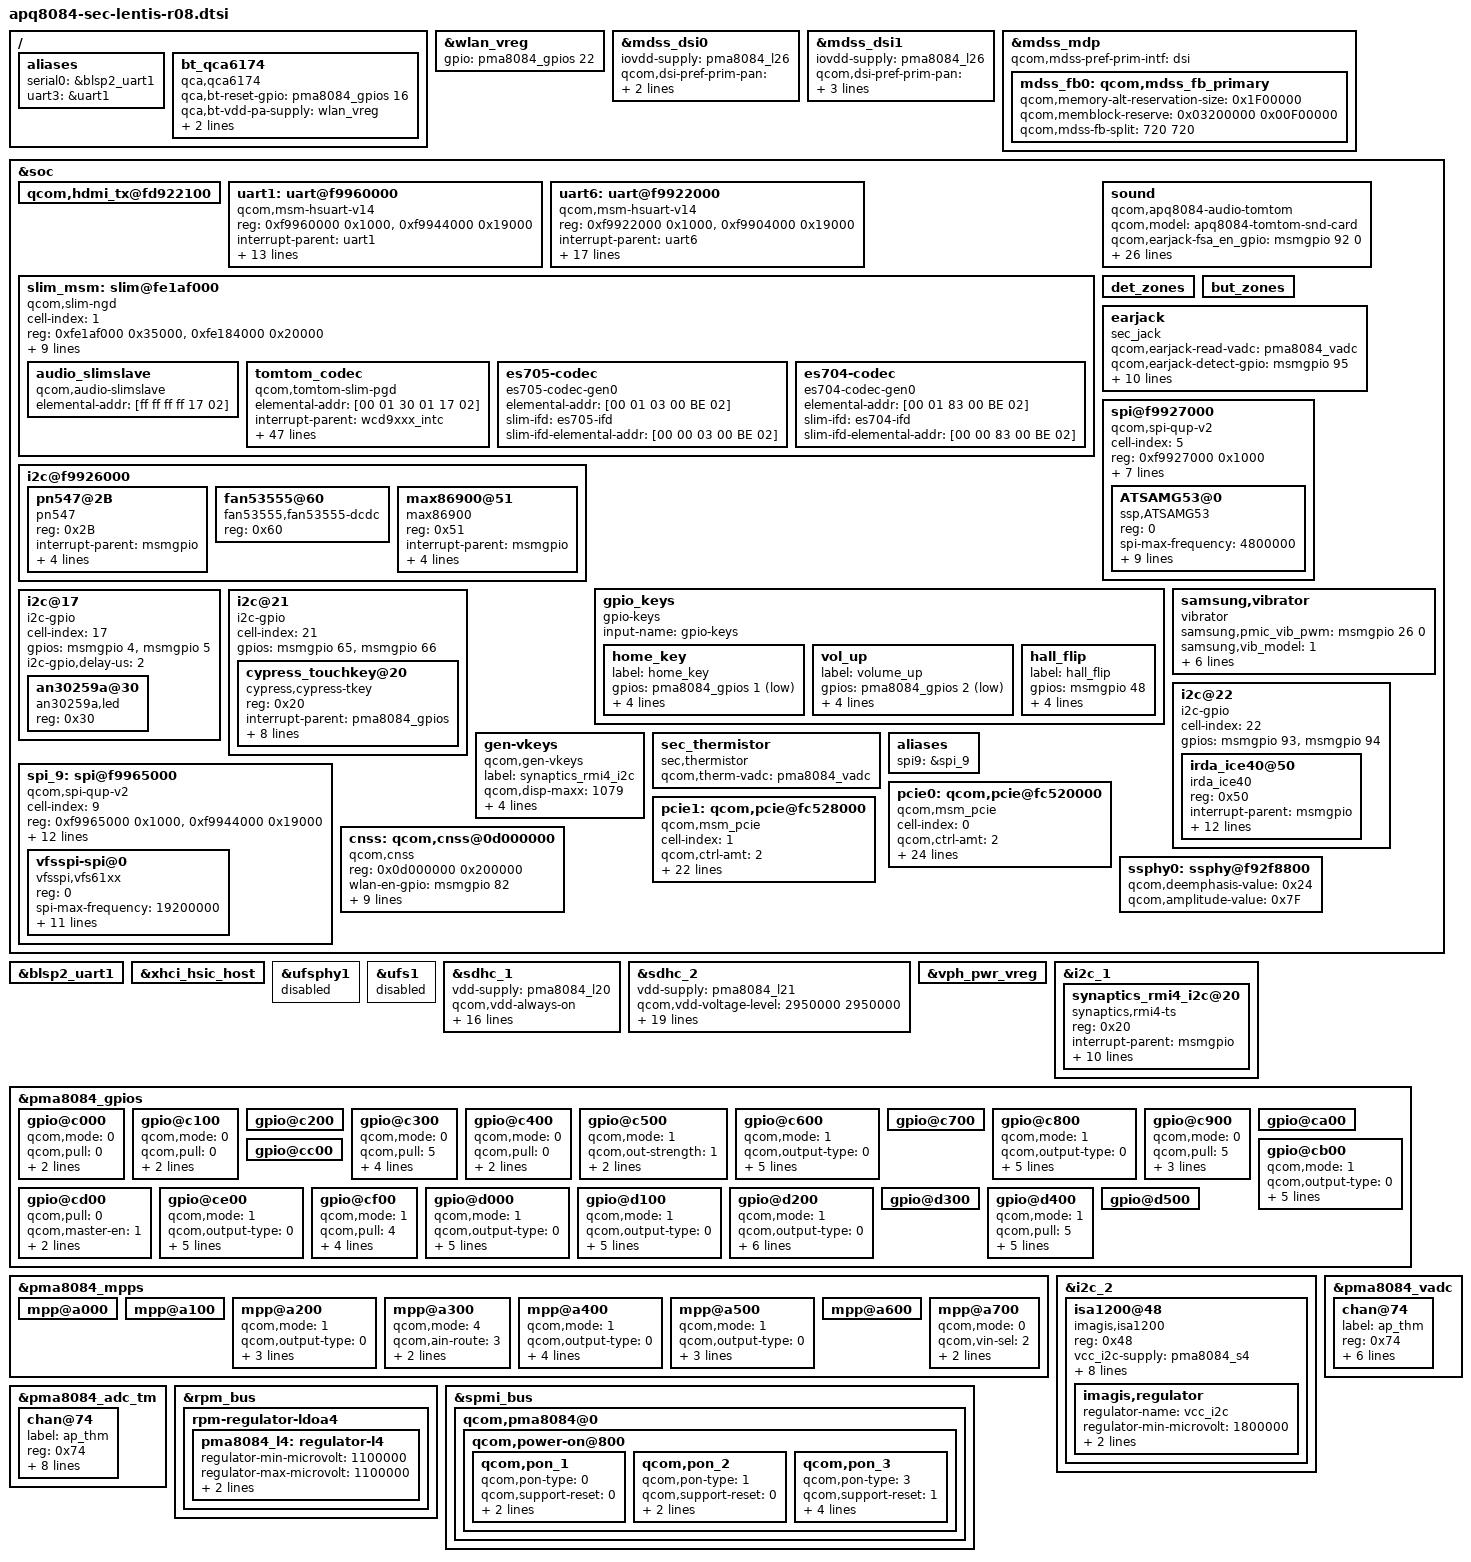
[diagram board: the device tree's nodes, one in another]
/* Copyright (c) 2013-2014, The Linux Foundation. All rights reserved.
 *
 * This program is free software; you can redistribute it and/or modify
 * it under the terms of the GNU General Public License version 2 and
 * only version 2 as published by the Free Software Foundation.
 *
 * This program is distributed in the hope that it will be useful,
 * but WITHOUT ANY WARRANTY; without even the implied warranty of
 * MERCHANTABILITY or FITNESS FOR A PARTICULAR PURPOSE.  See the
 * GNU General Public License for more details.
 */

#include "external-mdm9x25.dtsi"
#include "apq8084-camera-sensor-lentislte-r07.dtsi"
#include "apq8084-tdmb-lentis-r00.dtsi"
#include "apq8084-sii8240-mhl2-lentis-r00.dtsi"

/ {
	aliases {
		serial0 = &blsp2_uart1;
		uart3 = &uart1;
	};

	bt_qca6174 {
		compatible = "qca,qca6174";
		qca,bt-reset-gpio = <&pma8084_gpios 16 0>; /* BT_EN */
		qca,bt-vdd-pa-supply = <&wlan_vreg>;
		qca,bt-vdd-ldo-supply = <&pma8084_l27>;
		qca,bt-vdd-ldo-voltage-level = <1150000 1200000>;
	};
};

&wlan_vreg {
	gpio = <&pma8084_gpios 22 0>;
};

#include "../../../../drivers/video/msm/mdss/samsung/S6E3HA0_AMS510CW01/dsi_panel_S6E3HA0_AMS510CW01_wqhd_octa_cmd.dtsi"

&mdss_dsi0 {
		iovdd-supply = <&pma8084_l26>;
		qcom,dsi-pref-prim-pan = <&ss_dsi_panel_S6E3HA0_AMS510CW01_WQHD_0>;

		qcom,platform-te-gpio = <&msm_gpio 12 0>;
	};

&mdss_dsi1 {
		iovdd-supply = <&pma8084_l26>;
		qcom,dsi-pref-prim-pan = <&ss_dsi_panel_S6E3HA0_AMS510CW01_WQHD_1>;

		qcom,platform-reset-gpio = <&pma8084_gpios 21 0>;
		qcom,platform-enable-gpio = <&pma8084_gpios 6 0>;
	};

&mdss_mdp {
		qcom,mdss-pref-prim-intf = "dsi";

		mdss_fb0: qcom,mdss_fb_primary {
			qcom,memory-alt-reservation-size = <0x1F00000>;	 /* Framebuffer reservation only for LPM or recovery boot mode */
			qcom,memblock-reserve = <0x03200000 0x00F00000>;
			qcom,mdss-fb-split = <720 720>;
		};
	};

&soc {
	qcom,hdmi_tx@fd922100 {
		status = "ok";
	};

	uart1: uart@f9960000 {
		compatible = "qcom,msm-hsuart-v14";
		status = "ok";
		reg = <0xf9960000 0x1000>,
			<0xf9944000 0x19000>;
		reg-names = "core_mem", "bam_mem";
		interrupt-names = "core_irq", "bam_irq", "wakeup_irq";
	#address-cells = <0>;
		interrupt-parent = <&uart1>;
		interrupts = <0 1 2>;
	#interrupt-cells = <1>;
		interrupt-map-mask = <0xffffffff>;
		interrupt-map = <0 &intc 0 116 0 1 &intc 0 239 0 2 &msmgpio 60 0>;
		qcom,tx-gpio = <&msmgpio 59 0x00>;
		qcom,rx-gpio = <&msmgpio 60 0x00>;
		qcom,bam-tx-ep-pipe-index = <6>;
		qcom,bam-rx-ep-pipe-index = <7>;
		qcom,msm-bus,name = "uart1";
		qcom,msm-bus,num-cases = <2>;
		qcom,msm-bus,num-paths = <1>;
		qcom,msm-bus,vectors-KBps = <84 512 0 0>, <84 512 500 800>;
	};

	/* Use wakeup_irq in case of IBS */
	uart6: uart@f9922000 { /* BLSP1 UART6 */
		compatible = "qcom,msm-hsuart-v14";
		reg = <0xf9922000 0x1000>,
			<0xf9904000 0x19000>;
		reg-names = "core_mem", "bam_mem";
		interrupt-names = "core_irq", "bam_irq", "wakeup_irq";
		#address-cells = <0>;
		interrupt-parent = <&uart6>;
		interrupts = <0 1 2>;
		#interrupt-cells = <1>;
		interrupt-map-mask = <0xffffffff>;
		interrupt-map = <0 &intc 0 112 0
						1 &intc 0 238 0
						2 &msmgpio 44 0>;

		qcom,tx-gpio = <&msmgpio 43 0x00>;
		qcom,rx-gpio = <&msmgpio 44 0x00>;
		qcom,cts-gpio = <&msmgpio 45 0x00>;
		qcom,rfr-gpio = <&msmgpio 46 0x00>;

		qcom,inject-rx-on-wakeup;
		qcom,rx-char-to-inject = <0xfd>;

		qcom,bam-tx-ep-pipe-index = <10>;
		qcom,bam-rx-ep-pipe-index = <11>;
		qcom,msm-bus,name = "uart6";
		qcom,msm-bus,num-cases = <2>;
		qcom,msm-bus,num-paths = <1>;
		qcom,msm-bus,vectors-KBps =
				<86 512 0 0>,
				<86 512 500 800>;
		status = "ok";
	};

	slim_msm: slim@fe1af000 {
		cell-index = <1>;
		compatible = "qcom,slim-ngd";
		reg = <0xfe1af000 0x35000>,
		      <0xfe184000 0x20000>;
		reg-names = "slimbus_physical", "slimbus_bam_physical";
		interrupts = <0 163 0>, <0 164 0>;
		interrupt-names = "slimbus_irq", "slimbus_bam_irq";
		qcom,apps-ch-pipes = <0x60000000>;
		qcom,ea-pc = <0xb0>;
		qcom,slim-mdm = "esoc0";

		audio_slimslave {
			compatible = "qcom,audio-slimslave";
			elemental-addr = [ff ff ff ff 17 02];
		};

		/delete-node/ taiko_codec;

		tomtom_codec {
			compatible = "qcom,tomtom-slim-pgd";
			elemental-addr = [00 01 30 01 17 02];

			interrupt-parent = <&wcd9xxx_intc>;
			interrupts = <0 1 2 3 4 5 6 7 8 9 10 11 12 13 14 15 16
				      17 18 19 20 21 22 23 24 25 26 27 28 30 31>;

			qcom,cdc-reset-gpio = <&msmgpio 101 0>;

			cdc-vdd-buck-supply = <&pma8084_s5>;
			qcom,cdc-vdd-buck-voltage = <2150000 2150000>;
			qcom,cdc-vdd-buck-current = <650000>;

			cdc-vdd-tx-h-supply = <&pma8084_s4>;
			qcom,cdc-vdd-tx-h-voltage = <1800000 1800000>;
			qcom,cdc-vdd-tx-h-current = <25000>;

			cdc-vdd-rx-h-supply = <&pma8084_s4>;
			qcom,cdc-vdd-rx-h-voltage = <1800000 1800000>;
			qcom,cdc-vdd-rx-h-current = <25000>;

			cdc-vddpx-1-supply = <&pma8084_s4>;
			qcom,cdc-vddpx-1-voltage = <1800000 1800000>;
			qcom,cdc-vddpx-1-current = <10000>;

			cdc-vdd-a-1p2v-supply = <&pma8084_l1>;
			qcom,cdc-vdd-a-1p2v-voltage = <1225000 1225000>;
			qcom,cdc-vdd-a-1p2v-current = <10000>;

			cdc-vddcx-1-supply = <&pma8084_l1>;
			qcom,cdc-vddcx-1-voltage = <1225000 1225000>;
			qcom,cdc-vddcx-1-current = <10000>;

			cdc-vddcx-2-supply = <&pma8084_l1>;
			qcom,cdc-vddcx-2-voltage = <1225000 1225000>;
			qcom,cdc-vddcx-2-current = <10000>;

			qcom,cdc-static-supplies = "cdc-vdd-buck",
						   "cdc-vdd-tx-h",
						   "cdc-vdd-rx-h",
						   "cdc-vddpx-1",
						   "cdc-vdd-a-1p2v",
						   "cdc-vddcx-1",
						   "cdc-vddcx-2";

			qcom,cdc-micbias-ldoh-v = <0x3>;
			qcom,cdc-micbias-cfilt1-mv = <1800>;
			qcom,cdc-micbias-cfilt2-mv = <2700>;
			qcom,cdc-micbias-cfilt3-mv = <1800>;
			qcom,cdc-micbias1-cfilt-sel = <0x0>;
			qcom,cdc-micbias2-cfilt-sel = <0x1>;
			qcom,cdc-micbias3-cfilt-sel = <0x2>;
			qcom,cdc-micbias4-cfilt-sel = <0x2>;
			qcom,cdc-mclk-clk-rate = <9600000>;
			qcom,cdc-slim-ifd = "tomtom-slim-ifd";
			qcom,cdc-slim-ifd-elemental-addr = [00 00 30 01 17 02];
			qcom,cdc-dmic-sample-rate = <4800000>;
			qcom,cdc-variant = "WCD9330";
		};
	};

	sound {
		compatible = "qcom,apq8084-audio-tomtom";
		qcom,model = "apq8084-tomtom-snd-card";
		qcom,earjack-fsa_en_gpio = <&msmgpio 92 0>;

		qcom,audio-routing =
			"RX_BIAS", "MCLK",
			"LDO_H", "MCLK",
			"AIF4 MAD", "MCLK",
			"AMIC2", "MIC BIAS2 External",
			"MIC BIAS2 External", "Headset Mic",
			"DMIC1", "MIC BIAS1 External",
			"MIC BIAS1 External", "Digital Mic1",
			"DMIC2", "Main Mic Bias",
			"Main Mic Bias", "Main Mic",
			"DMIC3", "MIC BIAS3 External",
			"MIC BIAS3 External", "Digital Mic3",
			"DMIC4", "MIC BIAS1 External",
			"MIC BIAS1 External", "Sub Mic",
			"DMIC5", "MIC BIAS4 External",
			"MIC BIAS4 External", "Digital Mic5",
			"DMIC6", "MIC BIAS3 External",
			"MIC BIAS3 External", "Third Mic";

		qcom,codec-mclk-clk-freq = <9600000>;
		qcom,prim-auxpcm-gpio-clk  = <&msmgpio 87 0>;
		qcom,prim-auxpcm-gpio-sync = <&msmgpio 88 0>;
		qcom,prim-auxpcm-gpio-din  = <&msmgpio 89 0>;
		qcom,prim-auxpcm-gpio-dout = <&msmgpio 90 0>;
		qcom,prim-auxpcm-gpio-set = "prim-gpio-tert";
		qcom,sec-auxpcm-gpio-clk  = <&msmgpio 82 0>;
		qcom,sec-auxpcm-gpio-sync = <&msmgpio 83 0>;
		qcom,sec-auxpcm-gpio-dout = <&msmgpio 85 0>;
		qcom,cdc-micbias2-headset-only;
		qcom,micbias-en-msm-gpio = <&pma8084_mpps 3 0>;
		qcom,ext-mclk-gpio  = <&msmgpio 47 0>;
		qcom,hdmi-audio-rx;
	};

	det_zones: det_zones {
		#list-det-cells = <4>;
	};

	but_zones: but_zones {
		#list-but-cells = <3>;
	};

	earjack {
		compatible = "sec_jack";
		qcom,earjack-read-vadc = <&pma8084_vadc>;
		qcom,earjack-detect-gpio = <&msmgpio 95 0>;
		qcom,earjack-micbias-gpio = <&pma8084_gpios 11 0>;
		qcom,earjack-sendend-gpio = <&pma8084_gpios 4 0>;
		qcom,send-end-active-high;
		det-zones-list = <&det_zones 3 10000 10 0>,
						 <&det_zones 930 10000 10 0>,
						 <&det_zones 2400 10000 10 1>,
						 <&det_zones 9999 10000 10 1>;
		but-zones-list = <&but_zones 0 0 145>,
						 <&but_zones 1 146 310>,
						 <&but_zones 2 311 640>;
		mpp-channel-scaling = <4 1 3>;
	};

	i2c@f9926000 { /* BLSP1 QUP4 */
		pn547@2B {
			compatible = "pn547";
			reg = <0x2B>;
			interrupt-parent = <&msmgpio>;
			interrupts = <28 0>;
			pn547,irq-gpio = <&msmgpio 28 0x00>;
			pn547,ven-gpio = <&pma8084_mpps 5 0>;
			pn547,firm-gpio = <&msmgpio 16 0x00>;
		};
		fan53555@60 {
			compatible = "fan53555,fan53555-dcdc";
			reg = <0x60>;
		};
		max86900@51 {
			compatible = "max86900";
			reg = <0x51>;
			interrupt-parent = <&msmgpio>;
			interrupts = <78 0>;
			hrm_vreg-supply = <&pma8084_l16>;
			max86900,hrm_int-gpio = <&msmgpio 78 0x00>;
			max86900,hrm_pwr-1p8v = <&msmgpio 96 0x00>;
		};
	};

	spi@f9927000 {
		compatible = "qcom,spi-qup-v2";
		cell-index = <5>;
		#address-cells = <1>;
		#size-cells = <0>;
		reg = <0xf9927000 0x1000>;
		interrupt-names = "spi_irq";
		interrupts = <0 99 0>;
		spi-max-frequency = <19200000>;

		qcom,gpio-mosi = <&msmgpio 39 0>;
		qcom,gpio-miso = <&msmgpio 40 0>;
		qcom,gpio-clk  = <&msmgpio 42 0>;
		qcom,gpio-cs0  = <&msmgpio 41 0>;

		qcom,master-id = <86>;

		ATSAMG53@0 {
			compatible = "ssp,ATSAMG53";
			reg = <0>;
			spi-max-frequency = <4800000>;
			interrupt-parent = <&msmgpio>;
			interrupts = <67 0>;
			ssp,mcu_int1-gpio = <&msmgpio 67 0x00>;
			ssp,mcu_int2-gpio = <&msmgpio 9 0x00>;
			ssp,ap_int-gpio = <&msmgpio 143 0x00>;
			ssp,rst-gpio = <&msmgpio 77 0x00>;
			ssp,acc-position = <2>;
			ssp,mag-position = <4>;
			ssp,ap-rev = <8>;
		};
	};

	gpio_keys {
		compatible = "gpio-keys";
		input-name = "gpio-keys";

		home_key {
			label = "home_key";
			gpios = <&pma8084_gpios 1 0x1>;
			linux,input-type = <1>;
			linux,code = <172>;
			gpio-key,wakeup;
			debounce-interval = <15>;
		};

/*		vol_down {
			label = "volume_down";
			gpios = <&pma8084_gpios 5 0x0>;
			linux,input-type = <1>;
			linux,code = <114>;
			gpio-key,wakeup;
			debounce-interval = <15>;
		};
*/
		vol_up {
			label = "volume_up";
			gpios = <&pma8084_gpios 2 0x1>;
			linux,input-type = <1>;
			linux,code = <115>;
			gpio-key,wakeup;
			debounce-interval = <15>;
		};

		hall_flip {
			label = "hall_flip";
			gpios = <&msmgpio 48 0>;
			linux,input-type = <1>;
			linux,code = <21>;
			gpio-key,wakeup;
			debounce-interval = <15>;
		};
	};

	samsung,vibrator {
		compatible = "vibrator";
		samsung,pmic_vib_pwm = <&msmgpio 26 0>;
		samsung,vib_model = <1>;
		samsung,pmic_vib_en = <0>;
		samsung,pmic_haptic_pwr_en = <0>;
		samsung,is_pmic_vib_pwm = <0>;
		samsung,pwm_period_us = <40>;
		samsung,duty_us = <36>;
		samsung,motor_ic = <1>; /* MAX77828 : 0 , MAX77804K : 1 */
		status = "ok";
	};

	i2c@17 {
		cell-index = <17>;
		compatible = "i2c-gpio";

		gpios = <&msmgpio 4 0
			&msmgpio 5 0
			>;

		i2c-gpio,delay-us = <2>;
		#address-cells = <1>;
		#size-cells = <0>;
		an30259a@30 {
			compatible = "an30259a,led";
			reg = <0x30>;
		};
	};

	i2c@21 {
		cell-index = <21>;
		compatible = "i2c-gpio";
		gpios = <&msmgpio 65 0 /* sda */
		&msmgpio 66 0 /* scl */
		>;
		#address-cells = <1>;
		#size-cells = <0>;

		cypress_touchkey@20 {
			compatible = "cypress,cypress-tkey";
			reg = <0x20>;
			interrupt-parent = <&pma8084_gpios>;
			interrupts = <14 0>;
			vdd_led-supply = <&pma8084_l23>;
			vcc_en-supply = <&pma8084_lvs4>;
			cypress,scl-gpio = <&msmgpio 66 0x00>;
			cypress,sda-gpio = <&msmgpio 65 0x00>;
			cypress,irq-gpio = <&pma8084_gpios 14 0x1>;
			cypress,tkey-keycodes = <254 158>;
			cypress,led-ldo = <1>;
		};
	};

	i2c@22 {
		cell-index = <22>;
		compatible = "i2c-gpio";
		gpios = <&msmgpio 93 0 /* sda */
		&msmgpio 94 0 /* scl */
		>;
		#address-cells = <1>;
		#size-cells = <0>;

		irda_ice40@50 {
			compatible = "irda_ice40";
			reg = <0x50>;
			interrupt-parent = <&msmgpio>;
			interrupts = <23 0>;
			irda_ice40,fw_ver = <1>;
			vdd-supply = <&pma8084_l16>;
			irda_ice40,gpio_fpga_main_clk = <86>;
			irda_ice40,gpio_fpga_main_clk_func = <7>;
			irda_ice40,reset_n = <&msmgpio 80 0x00>;
			irda_ice40,sda-gpio = <&msmgpio 93 0x00>;
			irda_ice40,scl-gpio = <&msmgpio 94 0x00>;
			irda_ice40,irq-gpio = <&msmgpio 23 0x00>;
			irda_ice40,cdone = <&msmgpio 146 0x00>;
			irda_ice40,cresetb = <&pma8084_gpios 9 0x1>;
			irda_ice40,i2c-pull-up = <1>;
		};
	};

	gen-vkeys {
		compatible = "qcom,gen-vkeys";
		label = "synaptics_rmi4_i2c";
		qcom,disp-maxx = <1079>;
		qcom,disp-maxy = <1919>;
		qcom,panel-maxx = <1079>;
		qcom,panel-maxy = <2084>;
		qcom,key-codes = <158 139 102 217>;
	};

	sec_thermistor {
		compatible = "sec,thermistor";
		qcom,therm-vadc = <&pma8084_vadc>;
	};

	aliases {
		spi9 = &spi_9;
	};

	spi_9: spi@f9965000 {
		compatible = "qcom,spi-qup-v2";
		cell-index = <9>;
		#address-cells = <1>;
		#size-cells = <0>;
		reg = <0xf9965000 0x1000>,
			<0xf9944000 0x19000>;
		reg-names = "spi_physical", "spi_bam_physical";
		interrupt-names = "spi_irq", "spi_bam_irq";
		interrupts = <0 103 0>, <0 239 0>;
		spi-max-frequency = <19200000>;

		qcom,gpio-mosi = <&msmgpio 55 0>;
		qcom,gpio-miso = <&msmgpio 56 0>;
		qcom,gpio-clk  = <&msmgpio 58 0>;
		qcom,gpio-cs0  = <&msmgpio 57 0>;

		qcom,infinite-mode = <0>;
		qcom,use-bam;
		qcom,ver-reg-exists;
		qcom,bam-consumer-pipe-index = <16>;
		qcom,bam-producer-pipe-index = <17>;

		qcom,master-id = <84>;

		vfsspi-spi@0 {
			compatible = "vfsspi,vfs61xx";
			reg = <0>;
			spi-max-frequency = <19200000>;
			vfsspi-sleepPin = <&msmgpio 31 0x00>;
			vfsspi-drdyPin = <&msmgpio 79 0x01>;
			vfsspi-ldoPin = <&msmgpio 137 0x00>;
			vfsspi-ldoPin2 = <&msmgpio 72 0x00>;
			/* vfsspi-ocpflag = <&msmgpio 144 0x00>; */
			vfsspi-ocpen = <&msmgpio 136 0x00>;
			vfsspi-mosipin = <55>;
			vfsspi-misopin = <56>;
			vfsspi-cspin = <57>;
			vfsspi-clkpin = <58>;
			vfsspi-orient = <1>;
			vfsspi-ldocontrol= <1>;
		};
	};

	pcie0: qcom,pcie@fc520000 {
		compatible = "qcom,msm_pcie";
		cell-index = <0>;
		qcom,ctrl-amt = <2>;

		reg = <0xfc520000 0x2000>,
		      <0xfc526000 0x1000>,
		      <0xff000000 0x1000>,
		      <0xff001000 0x1000>,
		      <0xff100000 0x1000>,
		      <0xff200000 0x100000>,
		      <0xff300000 0xd00000>;

		reg-names = "parf", "phy", "dm_core", "elbi",
				"conf", "io", "bars";

		#address-cells = <0>;
		interrupt-parent = <&pcie0>;
		interrupts = <0 1 2 3 4 5 6 7 8 9 10 11 12>;
		#interrupt-cells = <1>;
		interrupt-map-mask = <0xffffffff>;
		interrupt-map = <0 &intc 0 243 0
				1 &intc 0 244 0
				2 &intc 0 245 0
				3 &intc 0 247 0
				4 &intc 0 248 0
				5 &intc 0 249 0
				6 &intc 0 250 0
				7 &intc 0 251 0
				8 &intc 0 252 0
				9 &intc 0 253 0
				10 &intc 0 254 0
				11 &intc 0 255 0
				12 &msmgpio 69 0x2>;
		interrupt-names = "int_msi", "int_a", "int_b", "int_c", "int_d",
				"int_pls_pme", "int_pme_legacy", "int_pls_err",
				"int_aer_legacy", "int_pls_link_up",
				"int_pls_link_down", "int_bridge_flush_n",
				"int_wake";

		perst-gpio = <&msmgpio 70 0>;
		wake-gpio = <&msmgpio 69 0>;
		clkreq-gpio = <&msmgpio 68 0>;

		gdsc-vdd-supply = <&gdsc_pcie_0>;
		vreg-1.8-supply = <&pma8084_l12>;
		vreg-0.9-supply = <&pma8084_l3>;
		vreg-3.3-supply = <&wlan_vreg>;

		qcom,ep-latency = <10>;

		qcom,msi-gicm-addr = <0xf9040040>;
		qcom,msi-gicm-base = <0x160>;
	};

	pcie1: qcom,pcie@fc528000 {
		compatible = "qcom,msm_pcie";
		cell-index = <1>;
		qcom,ctrl-amt = <2>;

		reg = <0xfc528000 0x2000>,
		    <0xfc52e000  0x1000>,
		    <0xfb000000 0x1000>,
		    <0xfb001000 0x1000>,
		    <0xfb100000 0x1000>,
		    <0xfb200000 0x100000>,
		    <0xfb300000 0xd00000>;

		reg-names = "parf", "phy", "dm_core", "elbi",
				"conf", "io", "bars";

		#address-cells = <0>;
		interrupt-parent = <&pcie1>;
		interrupts = <0 1 2 3 4 5 6 7 8 9 10 11 12>;
		#interrupt-cells = <1>;
		interrupt-map-mask = <0xffffffff>;
		interrupt-map = <0 &intc 0 271 0
				1 &intc 0 272 0
				2 &intc 0 273 0
				3 &intc 0 274 0
				4 &intc 0 275 0
				5 &intc 0 276 0
				6 &intc 0 277 0
				7 &intc 0 278 0
				8 &intc 0 279 0
				9 &intc 0 280 0
				10 &intc 0 281 0
				11 &intc 0 282 0
				12 &msmgpio 139 0x2>;

		interrupt-names = "int_msi", "int_a", "int_b", "int_c", "int_d",
				"int_pls_pme", "int_pme_legacy", "int_pls_err",
				"int_aer_legacy", "int_pls_link_up",
				"int_pls_link_down", "int_bridge_flush_n",
				"int_wake";

		perst-gpio = <&msmgpio 140 0>;
		wake-gpio = <&msmgpio 139 0>;
		clkreq-gpio = <&msmgpio 141 0>;

		gdsc-vdd-supply = <&gdsc_pcie_1>;
		vreg-1.8-supply = <&pma8084_l12>;
		vreg-0.9-supply = <&pma8084_l3>;

		qcom,msi-gicm-addr = <0xF9041040>;
		qcom,msi-gicm-base = <0x180>;
	};

	cnss: qcom,cnss@0d000000 {
		compatible = "qcom,cnss";
		reg = <0x0d000000 0x200000>;
		reg-names = "ramdump";
		wlan-en-gpio = <&msmgpio 82 0>;
		vdd-wlan-supply = <&wlan_vreg>;
		qcom,notify-modem-status;
		wlan-soc-swreg-supply = <&pma8084_l27>;

		qcom,msm-bus,name = "msm-cnss";
		qcom,msm-bus,num-cases = <4>;
		qcom,msm-bus,num-paths = <1>;
		qcom,msm-bus,vectors-KBps =
					  <45 512 0 0>, 		  /* No vote */
					  <45 512 6250 200000>,   /* 50 Mbps */
					  <45 512 25000 200000>,  /* 200 Mbps */
					  <45 512 100000 200000>; /* 800 Mbps */
	};

	ssphy0: ssphy@f92f8800 {
		qcom,deemphasis-value = <0x24>;
		qcom,amplitude-value = <0x7F>;
	};

};

&blsp2_uart1 {
	status = "ok";
};

&xhci_hsic_host {
	status = "ok";
};

&ufsphy1 {
	status = "disabled";
};

&ufs1 {
	status = "disabled";
};

&sdhc_1 {
	vdd-supply = <&pma8084_l20>;
	qcom,vdd-always-on;
	qcom,vdd-lpm-sup;
	qcom,vdd-voltage-level = <2950000 2950000>;
	qcom,vdd-current-level = <200 500000>;

	vdd-io-supply = <&pma8084_s4>;
	qcom,vdd-io-always-on;
	qcom,vdd-io-voltage-level = <1800000 1800000>;
	qcom,vdd-io-current-level = <200 154000>;

	qcom,pad-pull-on = <0x0 0x3 0x3 0x1>; /* no-pull, pull-up, pull-up, pull-down */
	qcom,pad-pull-off = <0x0 0x3 0x3 0x1>; /* no-pull, pull-up, pull-up, pull-down */
	qcom,pad-drv-on = <0x7 0x4 0x4>; /* 16mA, 10mA, 10mA */
	qcom,pad-drv-off = <0x0 0x0 0x0>; /* 2mA, 2mA, 2mA */

	qcom,clk-rates = <400000 20000000 25000000 50000000 100000000 192000000 384000000>;
	qcom,nonremovable;
	qcom,bus-speed-mode = "HS400_1p8v", "HS200_1p8v", "DDR_1p8v";
	status = "ok";
};

&sdhc_2 {
	vdd-supply = <&pma8084_l21>;
	qcom,vdd-voltage-level = <2950000 2950000>;
	qcom,vdd-current-level = <200 800000>;

	vdd-io-supply = <&pma8084_l13>;
	qcom,vdd-io-voltage-level = <1800000 2950000>;
	qcom,vdd-io-current-level = <200 22000>;

	qcom,pad-pull-on = <0x0 0x3 0x3>; /* no-pull, pull-up, pull-up */
	qcom,pad-pull-off = <0x0 0x3 0x3>; /* no-pull, pull-up, pull-up */
	qcom,pad-drv-on = <0x7 0x4 0x4>; /* 16mA, 10mA, 10mA */
	qcom,pad-drv-off = <0x0 0x0 0x0>; /* 2mA, 2mA, 2mA */

	qcom,clk-rates = <400000 20000000 25000000 50000000 100000000 200000000>;
	qcom,bus-speed-mode = "SDR12", "SDR25", "SDR50", "DDR50", "SDR104";

	#address-cells = <0>;
	interrupt-parent = <&sdhc_2>;
	interrupts = <0 1 2>;
	#interrupt-cells = <1>;
	interrupt-map-mask = <0xffffffff>;
	interrupt-map = <0 &intc 0 125 0
			1 &intc 0 221 0
			2 &msmgpio 122 0x3>;
	interrupt-names = "hc_irq", "pwr_irq", "status_irq";
	cd-gpios = <&msmgpio 122 0x1>;
	wp-gpios = <&msmgpio 75 0x1>;

	status = "ok";
};

&vph_pwr_vreg {
	status = "ok";
};

&slim_msm {
	tomtom_codec {
		qcom,cdc-micbias1-ext-cap;
		qcom,cdc-micbias3-ext-cap;

		/*
		 * spkrdrv supply in MTP device is from VPH_PWR which is
		 * always ON. Give a dummy supply to make codec driver happy.
		 */
		cdc-vdd-spkdrv-supply = <&vph_pwr_vreg>;
		qcom,cdc-vdd-spkdrv-voltage = <0 0>;
		qcom,cdc-vdd-spkdrv-current = <0>;

		qcom,cdc-on-demand-supplies = "cdc-vdd-spkdrv";
	};
};

&slim_msm {
	es705-gpioa-gpio = <&msmgpio 91 0>;
	es705-gpiob-gpio = <&msmgpio 76 0>;
	es705-uart-tx = <&msmgpio 59 0>;
	es705-uart-rx = <&msmgpio 60 0>;
	es705-reset-gpio = <&msmgpio 117 0>;

	es705-codec {
		compatible = "es705-codec-gen0";
		elemental-addr = [00 01 03 00 BE 02];
		slim-ifd = "es705-ifd";
		slim-ifd-elemental-addr = [00 00 03 00 BE 02];
	};

	es704-codec {
		compatible = "es704-codec-gen0";
		elemental-addr = [00 01 83 00 BE 02];
		slim-ifd = "es704-ifd";
		slim-ifd-elemental-addr = [00 00 83 00 BE 02];
	};
};

&i2c_1 {
	status = "okay";
	synaptics_rmi4_i2c@20 {
		compatible = "synaptics,rmi4-ts";
		reg = <0x20>;
		interrupt-parent = <&msmgpio>;
		interrupts = <145 0>;
		vcc_en-supply = <&pma8084_lvs3>;
		synaptics,supply-num = <1>;		/* the number of regulators */
		synaptics,supply-name = "8084_lvs3";	/* the name of regulators, in power-on order */
		synaptics,external_ldo = <&msmgpio 83 0x1>;
		synaptics,irq-gpio = <&msmgpio 145 0x1>;
		synaptics,tsp-coords = <1439 2559>;
		synaptics,i2c-pull-up = <1>;
		synaptics,tsp-project = "L";
		synaptics,tsp-extra_config = <0 0 0 0>;/* <"pwrctrl", "N", "N", "N"> */
	};
};

&pma8084_gpios {
	gpio@c000 { /* GPIO 1 */
		qcom,mode = <0>;
		qcom,pull = <0>;
		qcom,vin-sel = <2>;
		qcom,src-sel = <0>;
	};

	gpio@c100 { /* GPIO 2 */
		qcom,mode = <0>;
		qcom,pull = <0>;
		qcom,vin-sel = <2>;
		qcom,src-sel = <0>;
	};

	gpio@c200 { /* GPIO 3 */
	};

	gpio@c300 { /* GPIO 4 */
                qcom,mode = <0>;         /* Digital input */
                qcom,pull = <5>;         /* no pull */
                qcom,vin-sel = <2>;      /* VIN2 */
                qcom,src-sel = <0>;      /* GPIO */
                qcom,invert = <0>;       /* Invert */
                qcom,master-en = <1>;    /* Enable GPIO */
	};

	gpio@c400 { /* GPIO 5 */
		qcom,mode = <0>;
		qcom,pull = <0>;
		qcom,vin-sel = <2>;
		qcom,src-sel = <0>;
	};

	gpio@c500 { /* GPIO 6 */
		/* LCD_EN */
		qcom,mode = <1>;		/* Digital output */
		qcom,out-strength = <1>;	/* Low */
		qcom,src-sel = <0>;		/* Function 1  */
		qcom,master-en = <1>;
	};

	gpio@c600 { /* GPIO 7 */
		qcom,mode = <1>;		/* Digital output */
		qcom,output-type = <0>;		/* CMOS logic */
		qcom,invert = <0>;		/* Output low initially */
		qcom,vin-sel = <2>;		/* VIN 2 */
		qcom,src-sel = <0>;		/* GPIO */
		qcom,out-strength = <3>;	/* HIGH */
		qcom,master-en = <1>;		/* Enable GPIO */
	};

	gpio@c700 { /* GPIO 8 */
	};

	gpio@c800 { /* GPIO 9 */
		qcom,mode = <1>;		/* Digital output */
		qcom,output-type = <0>;		/* CMOS logic */
		qcom,invert = <0>;		/* Do not invert the output */
		qcom,vin-sel = <2>;		/* PMA8084 S4 = 1.8 V */
		qcom,src-sel = <0>;		/* GPIO */
		qcom,out-strength = <3>;	/* High drive strength */
		qcom,master-en = <1>;		/* Enable GPIO */
	};

	gpio@c900 { /* GPIO 10 */
		/* NFC clk request */
		qcom,mode = <0>;		/* QPNP_PIN_MODE_DIG_IN */
		qcom,pull = <5>;		/* QPNP_PIN_PULL_NO */
		qcom,vin-sel = <2>;		/* QPNP_PIN_VIN2 */
		qcom,src-sel = <2>;		/* QPNP_PIN_SEL_FUNC_1 */
		qcom,master-en = <1>;
	};

	gpio@ca00 { /* GPIO 11 */
		/* VBUS interrupt */
	};

	gpio@cb00 { /* GPIO 12 */
		qcom,mode = <1>;		/* Digital output */
		qcom,output-type = <0>;		/* CMOS logic */
		qcom,invert = <0>;		/* Output low initially */
		qcom,vin-sel = <2>;		/* VIN 2 */
		qcom,src-sel = <0>;		/* GPIO */
		qcom,out-strength = <2>;	/* Medium */
		qcom,master-en = <1>;		/* Enable GPIO */
	};

	gpio@cc00 { /* GPIO 13 */
	};

	gpio@cd00 { /* GPIO 14 */
		qcom,pull = <0>;		/* set to default pull */
		qcom,master-en = <1>;
		qcom,vin-sel = <2>;		/* select 1.8 V source */
		qcom,src-sel = <3>;
	};

	gpio@ce00 { /* GPIO 15 */
		qcom,mode = <1>;		/* Digital output */
		qcom,output-type = <0>;		/* CMOS logic */
		qcom,invert = <0>;		/* Output low initially */
		qcom,vin-sel = <2>;		/* VIN 2 */
		qcom,src-sel = <2>;		/* Function 1 */
		qcom,out-strength = <3>;	/* High */
		qcom,master-en = <1>;		/* Enable GPIO */
	};

	gpio@cf00 { /* GPIO 16 */
		qcom,mode = <1>;		/* Digital output*/
		qcom,pull = <4>;		/* Pulldown 10uA */
		qcom,vin-sel = <2>;		/* VIN2 */
		qcom,src-sel = <0>;		/* GPIO */
		qcom,invert = <0>;		/* Invert */
		qcom,master-en = <1>;		/* Enable GPIO */
	};

	gpio@d000 { /* GPIO 17 */
		qcom,mode = <1>;		/* Digital output */
		qcom,output-type = <0>;		/* CMOS logic */
		qcom,invert = <0>;		/* Output low initially */
		qcom,vin-sel = <2>;		/* VIN 2 */
		qcom,src-sel = <0>;		/* Function 1 */
		qcom,out-strength = <2>;	/* Medium */
		qcom,master-en = <1>;		/* Enable GPIO */
	};

	gpio@d100 { /* GPIO 18 */
		qcom,mode = <1>;		/* Digital output */
		qcom,output-type = <0>;		/* CMOS logic */
		qcom,invert = <0>;		/* Output low initially */
		qcom,vin-sel = <2>;		/* VIN 2 */
		qcom,src-sel = <3>;		/* Function 2 */
		qcom,out-strength = <2>;	/* Medium */
		qcom,master-en = <1>;		/* Enable GPIO */
	};

	gpio@d200 { /* GPIO 19 */
		qcom,mode = <1>;		/* Digital output */
		qcom,output-type = <0>;	/* CMOS logic */
		qcom,pull = <5>;			/* QPNP_PIN_PULL_NO */
		qcom,invert = <0>;		/* Output low initially */
		qcom,vin-sel = <2>;		/* PM8941 S3 = 1.8 V */
		qcom,src-sel = <0>;		/* Constant */
		qcom,out-strength = <2>;	/* Medium drive strength */
		qcom,master-en = <1>;	/* Enable GPIO */
	};

	gpio@d300 { /* GPIO 20 */
	};

	gpio@d400 { /* GPIO 21 */
		/* LCD_RESET */
		qcom,mode = <1>;		/* Digital output */
		qcom,pull = <5>;		/* Pull down */
		qcom,output-type = <0>;		/* CMOS */
		qcom,vin-sel = <2>;		/* PMA8084 S4 = 1.8 V */
		qcom,out-strength = <1>;	/* Low */
		qcom,src-sel = <0>;		/* constant */
		qcom,master-en = <1>;
	};

	gpio@d500 { /* GPIO 22 */
	};
};

&pma8084_mpps {
	mpp@a000 { /* MPP 1 */
	};

	mpp@a100 { /* MPP 2 */
	};

	mpp@a200 { /* MPP 3 */
		/* HDMI_5v_vreg regulator enable */
		qcom,mode = <1>;		/* Digital output */
		qcom,output-type = <0>;		/* CMOS logic */
		qcom,vin-sel = <2>;		/* VPH_PWR */
		qcom,src-sel = <0>;		/* Constant */
		qcom,master-en = <1>;		/* Enable GPIO */
	};

	mpp@a300 { /* MPP 4 */
		qcom,mode = <4>; /* AIN input */
		qcom,ain-route = <3>; /* AMUX 8 */
		qcom,master-en = <1>;/* Enable MPP4 */
		qcom,src-sel = <0>; /* Function constant */
	};

	mpp@a400 { /* MPP 5 */
		qcom,mode = <1>;		/* Digital output */
		qcom,output-type = <0>;		/* CMOS */
		qcom,vin-sel = <2>;		/* PMA8084 S4 = 1.8V > 1.6V */
		qcom,src-sel = <0>;		/* Constant */
		qcom,out-strength = <1>;	/* Low */
		qcom,master-en = <1>;
	};

	mpp@a500 { /* MPP 6 */
		qcom,mode = <1>;                /* Digital output */
		qcom,output-type = <0>;         /* CMOS */
		qcom,vin-sel = <2>;             /* PMA8084 S4 = 1.8V > 1.6V */
		qcom,src-sel = <0>;             /* Constant */
		/*qcom,out-strength = <1>;*/      /* Low */
		qcom,master-en = <1>;
	};

	mpp@a600 { /* MPP 7 */
	};

	mpp@a700 { /* MPP 8 */
		qcom,mode = <0>; /* DIG_IN */
		qcom,vin-sel = <2>; /* PMA8084_S3 1.8V > 1.6V */
		qcom,src-sel = <0>; /* CONSTANT */
		qcom,master-en = <1>; /* ENABLE MPP */
	};
};

&i2c_2 {
	isa1200@48 {
		status = "okay";
		reg = <0x48>;
		vcc_i2c-supply = <&pma8084_s4>;
		compatible = "imagis,isa1200";
		label = "vibrator";
		imagis,chip-en;
		imagis,need-pwm-clk;
		imagis,ext-clk-en;
		imagis,hap-en-gpio = <&msmgpio 48 0x00>;
		imagis,max-timeout = <15000>;
		imagis,pwm-div = <256>;
		imagis,mode-ctrl = <2>;
		imagis,regulator {
			regulator-name = "vcc_i2c";
			regulator-min-microvolt = <1800000>;
			regulator-max-microvolt = <1800000>;
			regulator-max-microamp = <9360>;
		};
	};
};

&pma8084_vadc {
	chan@74 {
		label = "ap_thm";
		reg = <0x74>;
		qcom,decimation = <0>;
		qcom,pre-div-channel-scaling = <0>;
		qcom,calibration-type = "ratiometric";
		qcom,scale-function = <2>;
		qcom,hw-settle-time = <2>;
		qcom,fast-avg-setup = <0>;
	};
};

&pma8084_adc_tm {
	chan@74 {
		label = "ap_thm";
		reg = <0x74>;
		qcom,decimation = <0>;
		qcom,pre-div-channel-scaling = <0>;
		qcom,calibration-type = "ratiometric";
		qcom,scale-function = <2>;
		qcom,hw-settle-time = <2>;
		qcom,fast-avg-setup = <3>;
		qcom,btm-channel-number = <0x69>;
		qcom,thermal-node;
	};
};
/* RPM controlled regulators: */
&rpm_bus {
	rpm-regulator-ldoa4 {
		status = "okay";
		pma8084_l4: regulator-l4 {
			regulator-min-microvolt = <1100000>;
			regulator-max-microvolt = <1100000>;
			qcom,init-voltage = <1100000>;
			status = "okay";
			regulator-always-on;
		};
	};
};

&spmi_bus {
	qcom,pma8084@0 {
		qcom,power-on@800 {
			qcom,pon_1 {
				qcom,pon-type = <0>;
				qcom,support-reset = <0>;
				qcom,pull-up = <1>;
				linux,code = <116>;
			};

			qcom,pon_2 {
				qcom,pon-type = <1>;
				qcom,support-reset = <0>;
				qcom,pull-up = <1>;
				linux,code = <114>;
			};

			qcom,pon_3 {
				qcom,pon-type = <3>;
				qcom,support-reset = <1>;
				qcom,s1-timer = <6720>;
				qcom,s2-timer = <1000>;
				qcom,s2-type = <1>;
				qcom,pull-up = <1>;
			};
		};
	};
};
